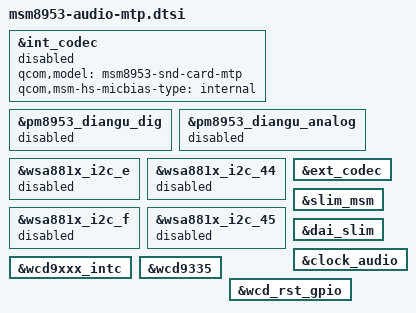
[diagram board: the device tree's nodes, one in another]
/*
 * Copyright (c) 2015-2016, The Linux Foundation. All rights reserved.
 *
 * This program is free software; you can redistribute it and/or modify
 * it under the terms of the GNU General Public License version 2 and
 * only version 2 as published by the Free Software Foundation.
 *
 * This program is distributed in the hope that it will be useful,
 * but WITHOUT ANY WARRANTY; without even the implied warranty of
 * MERCHANTABILITY or FITNESS FOR A PARTICULAR PURPOSE.  See the
 * GNU General Public License for more details.
 */

&int_codec {
	status = "disabled";
	qcom,model = "msm8953-snd-card-mtp";
	qcom,msm-hs-micbias-type = "internal";
};

&pm8953_diangu_dig {
	status = "disabled";
};

&pm8953_diangu_analog {
	status = "disabled";
};

&wsa881x_i2c_e {
	status = "disabled";
};

&wsa881x_i2c_44 {
	status = "disabled";
};

&wsa881x_i2c_f {
	status = "disabled";
};

&wsa881x_i2c_45 {
	status = "disabled";
};

&ext_codec {
	status = "okay";
};

&slim_msm {
        status = "okay";
};

&dai_slim {
        status = "okay";
};

&wcd9xxx_intc {
        status = "okay";
};

&clock_audio {
        status = "okay";
};

&wcd9335 {
        status = "okay";
};

&wcd_rst_gpio {
    status = "okay";
};

